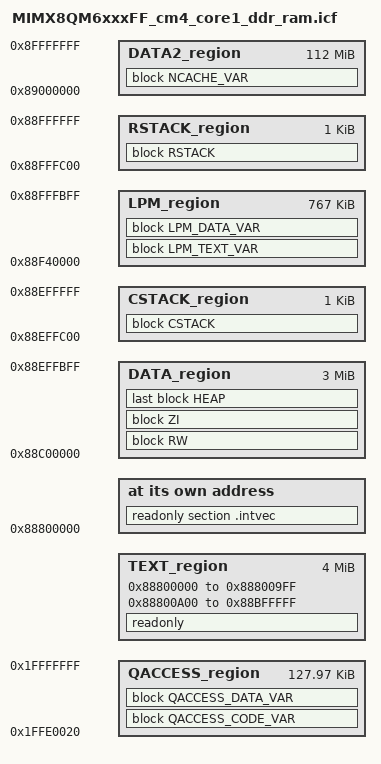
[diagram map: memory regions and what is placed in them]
/*
** ###################################################################
**     Processor:           MIMX8QM6AVUFF
**     Compiler:            IAR ANSI C/C++ Compiler for ARM
**     Reference manual:    IMX8QMRM, Rev. E, Jun. 2018
**     Version:             rev. 4.0, 2018-08-30
**     Build:               b180831
**
**     Abstract:
**         Linker file for the IAR ANSI C/C++ Compiler for ARM
**
**     Copyright 2016 Freescale Semiconductor, Inc.
**     Copyright 2016-2018 NXP
**     All rights reserved.
**     
**     SPDX-License-Identifier: BSD-3-Clause
**
**     http:                 www.nxp.com
**     mail:                 support@nxp.com
**
** ###################################################################
*/

/* DDR Memory region [0x88800000-0x8FFFFFFF] 120MB is allocated for CM4_1 */

define symbol m_interrupts_start       = 0x88800000;
define symbol m_interrupts_end         = 0x888009FF;

define symbol m_text_start             = 0x88800A00;
define symbol m_text_end               = 0x88BFFFFF;

define symbol m_data_start             = 0x88C00000;
define symbol m_data_end               = 0x88EFFFFF;

/* DDR Memory region [0x88F00000-0x88FFFFFF] 1MB is allocated for CM4_1 LPM resume memory */
define symbol m_resume_start           = 0x88F00000;
define symbol m_resume_end             = 0x88FFFFFF;

define symbol m_data2_start            = 0x89000000;
define symbol m_data2_end              = 0x8FFFFFFF;

/* M4 always start up from TCM. The SCU will copy the first 32 bytes of the binary to TCM
if the start address is not TCM. The TCM region [0x1FFE0000-0x1FFE001F] is reserved for this purpose. */
define symbol m_tcml_start             = 0x1FFE0020;
define symbol m_tcml_end               = 0x1FFFFFFF;

define symbol m_tcmu_start             = 0x20000000;
define symbol m_tcmu_end               = 0x2001FFFF;
/* Sizes */
if (isdefinedsymbol(__stack_size__)) {
  define symbol __size_cstack__        = __stack_size__;
} else {
  define symbol __size_cstack__        = 0x400;
}

if (isdefinedsymbol(__resume_stack_size__)) {
  define symbol __size_rstack__        = __resume_stack_size__;
} else {
  define symbol __size_rstack__        = 0x0400;
}

if (isdefinedsymbol(__heap_size__)) {
  define symbol __size_heap__          = __heap_size__;
} else {
  define symbol __size_heap__          = 0x400;
}

/* TCM size 256 KB */
if (isdefinedsymbol(__tcm_mem_size__)) {
  define symbol __size_tcm__        = __tcm_mem_size__;
} else {
  define symbol __size_tcm__         = 0x40000;
}

define exported symbol __CACHE_REGION_START   = m_interrupts_start;
define exported symbol __CACHE_REGION_SIZE    = m_resume_end - m_interrupts_start + 1 ;
define exported symbol __BACKUP_REGION_START  = m_resume_start; /* Symbol used in lpm_asm.s for TCM backup */

define memory mem with size = 4G;
define region TEXT_region = mem:[from m_interrupts_start to m_interrupts_end]
                          | mem:[from m_text_start to m_text_end];
define region DATA_region = mem:[from m_data_start to m_data_end-__size_cstack__];
define region CSTACK_region = mem:[from m_data_end-__size_cstack__+1 to m_data_end];
define region DATA2_region = mem:[from m_data2_start to m_data2_end];
define region QACCESS_region = mem:[from m_tcml_start to m_tcml_end];
define region LPM_region = mem:[from m_resume_start+__size_tcm__ to m_resume_end-__size_rstack__];
define region RSTACK_region = mem: [from m_resume_end-__size_rstack__+1 to m_resume_end];

define block CSTACK    with alignment = 8, size = __size_cstack__   { };
/* Stack used during suspend and resume */
define block RSTACK    with alignment = 8, size = __size_rstack__   { };
define block HEAP      with alignment = 8, size = __size_heap__     { };
define block RW        { readwrite };
define block ZI        { zi };
define block NCACHE_VAR    { section NonCacheable , section NonCacheable.init };
define block QACCESS_CODE_VAR   with alignment = 32 { section CodeQuickAccess };
define block QACCESS_DATA_VAR   with alignment = 32 { section DataQuickAccess };
define block LPM_TEXT_VAR   with alignment = 8 { section TextLpm };
define block LPM_DATA_VAR   with alignment = 8 { section DataLpm };

initialize by copy { readwrite, section .textrw, section DataQuickAccess, section CodeQuickAccess, section TextLpm, section DataLpm };
do not initialize  { section .noinit };

place at address mem: m_interrupts_start    { readonly section .intvec };
place in TEXT_region                        { readonly };
place in DATA_region                        { block RW };
place in DATA_region                        { block ZI };
place in DATA_region                        { last block HEAP };
place in CSTACK_region                      { block CSTACK };
place in RSTACK_region                      { block RSTACK};
place in DATA2_region                       { block NCACHE_VAR };
place in QACCESS_region                     { block QACCESS_CODE_VAR };
place in QACCESS_region                     { block QACCESS_DATA_VAR };
place in LPM_region                         { block LPM_TEXT_VAR };
place in LPM_region                         { block LPM_DATA_VAR };
